AUTOSAR XML (schema 4-0-3)
standard types defined: Boolean
package /AUTOSAR_Platform/DataConstrs
  range DC_Boolean: raw 0..1
package /PATAC/MSM/ComponentTypes
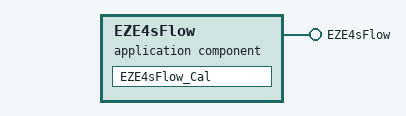
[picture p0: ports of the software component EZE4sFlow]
  application sw component type EZE4sFlow
    provide port EZE4sFlow: server-com-spec{operation=Cal, queue-length=1}, provided-interface=EZE4sFlow
    behavior EZE4sFlow_InternalBehavior
      operation invoked event OIT_EZE4sFlow_Cal_EZE4sFlow_Cal: start-on-event=EZE4sFlow_Cal, operation=EZE4sFlow.Cal
      runnable EZE4sFlow_Cal
  swc implementation EZE4sFlow_Implementation: behavior=EZE4sFlow_InternalBehavior
    code-descriptors:
      code Default: artifact-descriptors=autosar-engineering-object={short-label=Default, category=SWSRC}
package /PATAC/MSM/ModeAdjust/PortInterface
  client server interface EZE4sFlow
    operation Cal
      9 x arg, all with server-argument-impl-policy=USE-ARGUMENT-TYPE:
        BkReclnStgDone: type=Implementation/Boolean, direction=IN
        HdrstUpwdDnwdStgDone: type=Implementation/Boolean, direction=IN
        HdrstFrwdBkwdStgDone: type=Implementation/Boolean, direction=IN
        SecRwStFrwdBkwdStgDone: type=DataTypes/Boolean, direction=IN
        Chkhdflg: type=Implementation/Boolean, direction=IN
        BkReclnEn: type=Implementation/Boolean, direction=OUT
        HdrstUpwdEn: type=Implementation/Boolean, direction=OUT
        HdrstFrwdEn: type=Implementation/Boolean, direction=OUT
        SecRwStFrwdBkwdEn: type=DataTypes/Boolean, direction=OUT
